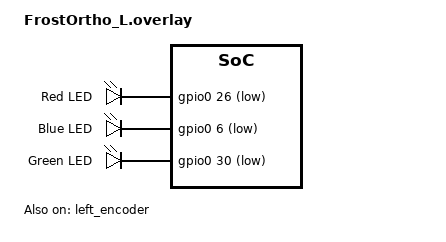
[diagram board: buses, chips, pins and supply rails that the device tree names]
#include "FrostOrtho.dtsi"
#include <behaviors/battery_history_request.dtsi>

&kscan0 {
        col-gpios
            = <&xiao_d 10 GPIO_ACTIVE_HIGH>
            , <&xiao_d 9 GPIO_ACTIVE_HIGH> 
            , <&xiao_d 8 GPIO_ACTIVE_HIGH> 
            , <&xiao_d 7 GPIO_ACTIVE_HIGH> 
            , <&gpio0 10 GPIO_ACTIVE_HIGH>
            , <&gpio0 9 GPIO_ACTIVE_HIGH>
            ;
};

&left_encoder {
    status = "okay";
};

/ {
    /* ここで ZMK に「どの色がどのLEDノードか」を教えます */
    aliases {
        led-red = &led_red;
        led-green = &led_green;
        led-blue = &led_blue;
    };

    /* ここで各ピンの色を定義します */
    leds {
        compatible = "gpio-leds";
        led_red: led_0 {
            gpios = <&gpio0 26 GPIO_ACTIVE_LOW>;
            label = "Red LED";
        };
        led_blue: led_1 {
            gpios = <&gpio0 6 GPIO_ACTIVE_LOW>;
            label = "Blue LED";
        };
        led_green: led_2 {
            gpios = <&gpio0 30 GPIO_ACTIVE_LOW>;
            label = "Green LED";
        };
    };
};
